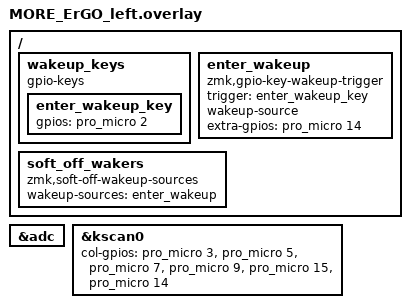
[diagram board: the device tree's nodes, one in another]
#include "MORE_ErGO.dtsi"
#include <zephyr/dt-bindings/input/input-event-codes.h>

&adc { status = "okay"; };

// / {
//     anin0: analog_input_0 {
//         compatible = "zmk,analog-input";
//         sampling-hz = <100>;
//         x-ch {
//             io-channels = <&adc 5>;      // ← AIN del eje X (0=P0.02, 5=P0.29, 7=P0.31...) AJÚSTALO
//             mv-mid = <1650>;             // voltaje en reposo (MÍDELO)
//             mv-min-max = <1600>;
//             mv-deadzone = <40>;
//             scale-multiplier = <1>;
//             scale-divisor = <100>;
//             evt-type = <INPUT_EV_REL>;
//             input-code = <INPUT_REL_HWHEEL>;  // scroll lateral
//         };
//         y-ch {
//             io-channels = <&adc 7>;      // ← AIN del eje Y AJÚSTALO
//             mv-mid = <1650>;
//             mv-min-max = <1600>;
//             mv-deadzone = <40>;
//             scale-multiplier = <1>;
//             scale-divisor = <100>;
//             evt-type = <INPUT_EV_REL>;
//             input-code = <INPUT_REL_WHEEL>;   // scroll vertical
//         };
//     };

//     anin0_listener {
//         compatible = "zmk,input-listener";
//         device = <&anin0>;
//     };
// };

&kscan0 {
    col-gpios
        = <&pro_micro 3 GPIO_ACTIVE_HIGH>
        , <&pro_micro 5 GPIO_ACTIVE_HIGH>
        , <&pro_micro 7 GPIO_ACTIVE_HIGH>
        , <&pro_micro 9 GPIO_ACTIVE_HIGH>
        , <&pro_micro 15 GPIO_ACTIVE_HIGH>
        , <&pro_micro 14 GPIO_ACTIVE_HIGH>
        ;
};
// ── Encender desde soft off SOLO con ENTER (posición 28 = RC(3,5) = col 5, fila 3) ──
// Al entrar en soft off, ZMK pone en alto únicamente la columna de ENTER (extra-gpios)
// y deja escuchando la fila de ENTER. Así ninguna otra tecla de esa fila puede despertarlo.
/ {
    wakeup_keys {
        compatible = "gpio-keys";
        enter_wakeup_key: enter_wakeup_key {
            gpios = <&pro_micro 2 (GPIO_ACTIVE_HIGH | GPIO_PULL_DOWN)>;   // fila 3 (entrada)
        };
    };

    enter_wakeup: enter_wakeup {
        compatible = "zmk,gpio-key-wakeup-trigger";
        trigger = <&enter_wakeup_key>;
        wakeup-source;
        extra-gpios = <&pro_micro 14 GPIO_ACTIVE_HIGH>;                  // columna 5 (salida)
    };

    soft_off_wakers {
        compatible = "zmk,soft-off-wakeup-sources";
        wakeup-sources = <&enter_wakeup>;
    };
};
